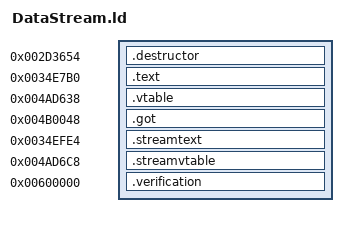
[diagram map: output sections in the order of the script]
OUTPUT_FORMAT("elf32-littlearm")
OUTPUT_ARCH(arm)
ENTRY(_Z11IsBigEndianv)
INCLUDE build/matches/data-stream/retail-symbols.ld
"_ZdlPv" = 0x001c42b0;
"_Znaj" = 0x001c3ff8;
strlen = 0x001c48bc;
__stack_chk_fail = 0x001c42e0;
__cxa_pure_virtual = 0;
SECTIONS {
    .destructor 0x002d3654 : { *data-stream.o(.text._ZN10DataStreamD1Ev) }
    .text 0x0034e7b0 : {
        *data-stream.o(.text._Z11IsBigEndianv)
        *data-stream.o(.text._ZN10DataStream4ReadEPvi)
        *data-stream.o(.text._ZN10DataStream5WriteEPKvi)
        *data-stream.o(.text._ZN10DataStream4SeekEii)
        *data-stream.o(.text._ZNK10DataStream4TellEv)
        *data-stream.o(.text._ZN10DataStream4SkipEi)
        *data-stream.o(.text._ZN10DataStream17ReadUnsignedShortEv)
        *data-stream.o(.text._ZN10DataStream9ReadShortEv)
        *data-stream.o(.text._ZN10DataStream9ReadFloatEv)
        *data-stream.o(.text._ZN10DataStream7ReadUTFEPci)
        *data-stream.o(.text._ZN10DataStream5Peek1Ev)
        *data-stream.o(.text._ZN10DataStreamD0Ev)
        *data-stream.o(.text._ZN10DataStream9WriteByteEi)
        *data-stream.o(.text._ZN10DataStream12WriteBooleanEb)
        *data-stream.o(.text._ZN10DataStream16ReadUnsignedByteEv)
        *data-stream.o(.text._ZN10DataStream8ReadByteEv)
        *data-stream.o(.text._ZN10DataStream11ReadBooleanEv)
        *data-stream.o(.text._ZN10DataStream7ReadIntEv)
        *data-stream.o(.text._ZN10DataStream21ReadAndAllocateStringEv)
        *data-stream.o(.text._ZN10DataStream10ReadStringEPci)
        *data-stream.o(.text._ZN10DataStream5Peek4Ev)
        *data-stream.o(.text._ZN10DataStream10WriteFloatEf)
        *data-stream.o(.text._ZN10DataStream8WriteIntEi)
        *data-stream.o(.text._ZN10DataStream5Peek2Ev)
        *data-stream.o(.text._ZN10DataStream10WriteShortEi)
        *data-stream.o(.text._ZN10DataStream8WriteUTFEPKc)
        *data-stream.o(.text._ZN10DataStreamC1ER6StreamNS_6endianE .text._ZN10DataStreamC2ER6StreamNS_6endianE)
    }
    .vtable 0x004ad638 : { *data-stream.o(.data.rel.ro) }
    .got 0x004b0048 : { *(.got.plt) . = 0x360; *(.got) }
    .streamtext 0x0034efe4 : {
        *stream.o(.text._ZN6StreamC1Ev .text._ZN6StreamC2Ev)
        *stream.o(.text._ZN6Stream5CloseEv)
        *stream.o(.text._ZN6Stream4ReadEv)
        *stream.o(.text._ZN6Stream5WriteEc)
        *stream.o(.text._ZN6Stream5WriteERS_i)
        *stream.o(.text._ZN6Stream4PeekEPvi)
        *stream.o(.text._ZN6StreamD0Ev .gnu.linkonce.t._ZN6StreamD0Ev)
        *stream.o(.text._ZN6StreamD1Ev .text._ZN6StreamD2Ev .gnu.linkonce.t._ZN6StreamD1Ev .gnu.linkonce.t._ZN6StreamD2Ev)
    }
    .streamvtable 0x004ad6c8 : { *stream.o(.data.rel.ro) }
    .verification 0x00600000 : { *retail-got.o(.text) }
}
